# STM32G473xx register map
File version: 1.0
Registers are 32-bit, read-write, reset 0x0 unless marked. A register's access mark holds for its fields unless they carry their own. Offsets are from the block's base; [hi:lo] are bit positions; {n}, {i} and the like mark numbered series.

## TIM2 — TIM
Base 0x40000000
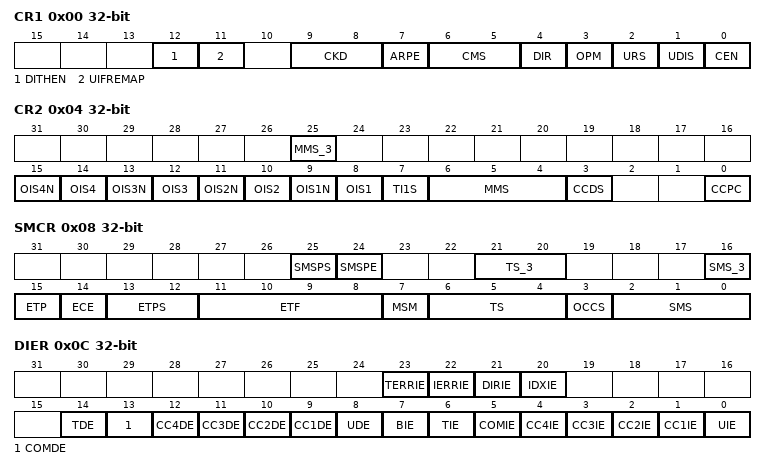
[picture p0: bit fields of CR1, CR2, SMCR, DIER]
0x00 CR1 — TIM control register 1
  [12] DITHEN — Dithering enable
  [11] UIFREMAP — Update interrupt flag remap
  [9:8] CKD — CKD[1:0] bits (clock division)
    0=DIV1 (tDTS=tCK_INT); 1=DIV2 (tDTS=2*tCK_INT); 2=DIV4 (tDTS=4*tCK_INT)
  [7] ARPE — Auto-reload preload enable
  [6:5] CMS — CMS[1:0] bits (Center-aligned mode selection)
  [4] DIR — Direction
    0=UP (Timer counter counts up); 1=DOWN (Timer counter counts down)
  [3] OPM — One pulse mode
    1=SINGLE (Counter stops counting at the next update event); 0=REPETITIVE (Counter is not stopped at update event)
  [2] URS — Update request source
    0=REGULAR (Counter overflow/underflow, Setting the UG bit or Update generation through the slave mode controller generates an update request); 1=COUNTER (Only counter overflow/underflow generates an update request)
  [1] UDIS — Update disable
  [0] CEN — Counter enable
0x04 CR2 — TIM control register 2
  [25] MMS_3 — MMS[3:0] bits (Master Mode Selection)
  [2n+7] OIS{n}N (n=1..4) — Output Idle state {n} (OC{n}N output)
  [2n+6] OIS{n} (n=1..4) — Output Idle state {n} (OC{n} output)
  [7] TI1S — TI1 Selection
  [6:4] MMS — MMS[3:0] bits (Master Mode Selection)
  [3] CCDS — Capture/Compare DMA Selection
    0=CC (CCx DMA request sent when CCx event occurs); 1=UPDATE (CCx DMA requests sent when update event occurs)
  [0] CCPC — Capture/Compare Preloaded Control
0x08 SMCR — TIM slave mode control register
  [25] SMSPS — SMS preload source
    0=TIMUPDATE (The SMS preload transfer is triggered by the Timer's Update event); 1=INDEX (The SMS preload transfer is triggered by the Index event)
  [24] SMSPE — SMS preload enable
  [21:20] TS_3 — TS[2:0] bits (Trigger selection)
  [16] SMS_3 — SMS[2:0] bits (Slave mode selection)
  [15] ETP — External trigger polarity
  [14] ECE — External clock enable
  [13:12] ETPS — ETPS[1:0] bits (External trigger prescaler)
  [11:8] ETF — ETF[3:0] bits (External trigger filter)
  [7] MSM — Master/slave mode
  [6:4] TS — TS[2:0] bits (Trigger selection)
  [3] OCCS — OCREF clear selection
  [2:0] SMS — SMS[2:0] bits (Slave mode selection)
0x0C DIER — TIM DMA/interrupt enable register
  [23] TERRIE — Encoder transition error enable
  [22] IERRIE — Encoder index error enable
  [21] DIRIE — Encoder direction change interrupt enable
  [20] IDXIE — Encoder index interrupt enable
  [14] TDE — Trigger DMA request enable
  [13] COMDE — COM DMA request enable
  [n+8] CC{n}DE (n=1..4) — Capture/Compare {n} DMA request enable
  [8] UDE — Update DMA request enable
  [7] BIE — Break interrupt enable
  [6] TIE — Trigger interrupt enable
  [5] COMIE — COM interrupt enable
  [n] CC{n}IE (n=1..4) — Capture/Compare {n} interrupt enable
  [0] UIE — Update interrupt enable
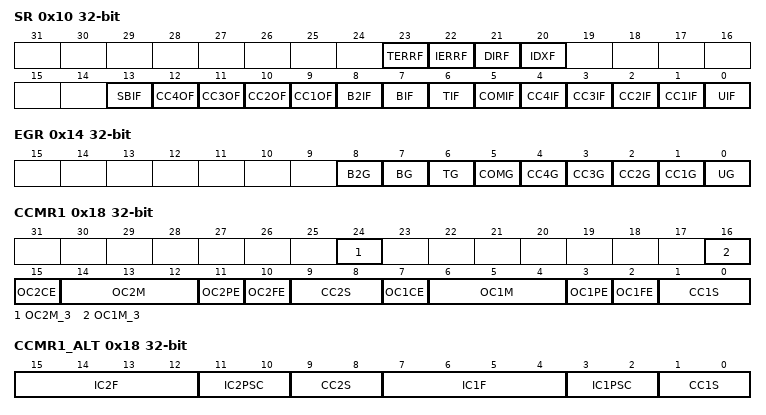
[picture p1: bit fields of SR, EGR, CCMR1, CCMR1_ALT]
0x10 SR — TIM status register
  [23] TERRF — Encoder transition error flag
  [22] IERRF — Encoder index error flag
  [21] DIRF — Encoder direction change interrupt flag
  [20] IDXF — Encoder index interrupt flag
  [13] SBIF — System Break interrupt Flag
  [n+8] CC{n}OF (n=1..4) — Capture/Compare {n} Overcapture Flag
  [8] B2IF — Break 2 interrupt Flag
  [7] BIF — Break interrupt Flag
  [6] TIF — Trigger interrupt Flag
  [5] COMIF — COM interrupt Flag
  [n] CC{n}IF (n=1..4) — Capture/Compare {n} interrupt Flag
  [0] UIF — Update interrupt Flag
0x14 EGR — TIM event generation register
  [8] B2G — Break 2 Generation
  [7] BG — Break Generation
  [6] TG — Trigger Generation
  [5] COMG — Capture/Compare Control Update Generation
  [n] CC{n}G (n=1..4) — Capture/Compare {n} Generation
  [0] UG — Update Generation
0x18 CCMR1 — TIM capture/compare mode register 1
  [24] OC2M_3 — OC2M[2:0] bits (Output Compare 2 Mode)
  [16] OC1M_3 — OC1M[2:0] bits (Output Compare 1 Mode)
  [15] OC2CE — Output Compare 2 Clear Enable
  [14:12] OC2M — OC2M[2:0] bits (Output Compare 2 Mode)
  [11] OC2PE — Output Compare 2 Preload enable
  [10] OC2FE — Output Compare 2 Fast enable
  [9:8] CC2S — CC2S[1:0] bits (Capture/Compare 2 Selection)
  [7] OC1CE — Output Compare 1 Clear Enable
  [6:4] OC1M — OC1M[2:0] bits (Output Compare 1 Mode)
  [3] OC1PE — Output Compare 1 Preload enable
  [2] OC1FE — Output Compare 1 Fast enable
  [1:0] CC1S — CC1S[1:0] bits (Capture/Compare 1 Selection)
0x18 CCMR1_ALT (alternate view of CCMR1) — TIM capture/compare mode register 1
  [15:12] IC2F — IC2F[3:0] bits (Input Capture 2 Filter)
  [11:10] IC2PSC — IC2PSC[1:0] bits (Input Capture 2 Prescaler)
  [9:8] CC2S — CC2S[1:0] bits (Capture/Compare 2 Selection)
  [7:4] IC1F — IC1F[3:0] bits (Input Capture 1 Filter)
  [3:2] IC1PSC — IC1PSC[1:0] bits (Input Capture 1 Prescaler)
  [1:0] CC1S — CC1S[1:0] bits (Capture/Compare 1 Selection)
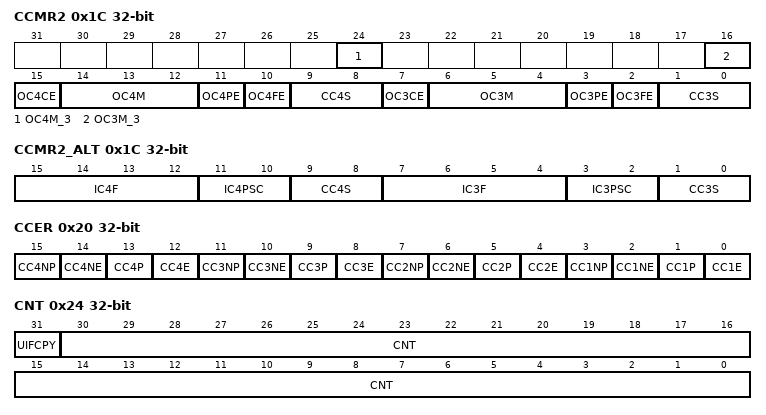
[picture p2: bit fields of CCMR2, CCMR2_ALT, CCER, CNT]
0x1C CCMR2 — TIM capture/compare mode register 2
  [24] OC4M_3 — OC4M[2:0] bits (Output Compare 4 Mode)
  [16] OC3M_3 — OC3M[2:0] bits (Output Compare 3 Mode)
  [15] OC4CE — Output Compare 4 Clear Enable
  [14:12] OC4M — OC4M[2:0] bits (Output Compare 4 Mode)
  [11] OC4PE — Output Compare 4 Preload enable
  [10] OC4FE — Output Compare 4 Fast enable
  [9:8] CC4S — CC4S[1:0] bits (Capture/Compare 4 Selection)
  [7] OC3CE — Output Compare 3 Clear Enable
  [6:4] OC3M — OC3M[2:0] bits (Output Compare 3 Mode)
  [3] OC3PE — Output Compare 3 Preload enable
  [2] OC3FE — Output Compare 3 Fast enable
  [1:0] CC3S — CC3S[1:0] bits (Capture/Compare 3 Selection)
0x1C CCMR2_ALT (alternate view of CCMR2) — TIM capture/compare mode register 2
  [15:12] IC4F — IC4F[3:0] bits (Input Capture 4 Filter)
  [11:10] IC4PSC — IC4PSC[1:0] bits (Input Capture 4 Prescaler)
  [9:8] CC4S — CC4S[1:0] bits (Capture/Compare 4 Selection)
  [7:4] IC3F — IC3F[3:0] bits (Input Capture 3 Filter)
  [3:2] IC3PSC — IC3PSC[1:0] bits (Input Capture 3 Prescaler)
  [1:0] CC3S — CC3S[1:0] bits (Capture/Compare 3 Selection)
0x20 CCER — TIM capture/compare enable register
  [4n-1] CC{n}NP (n=1..4) — Capture/Compare {n} Complementary output Polarity
  [4n-2] CC{n}NE (n=1..4) — Capture/Compare {n} Complementary output enable
  [4n-3] CC{n}P (n=1..4) — Capture/Compare {n} output Polarity
  [4n-4] CC{n}E (n=1..4) — Capture/Compare {n} output enable
0x24 CNT — TIM counter register
  [31] UIFCPY — Update interrupt flag copy (if UIFREMAP=1)
  [30:0] CNT — Counter Value
0x28 PSC — TIM prescaler
  [15:0] PSC — Prescaler Value
0x2C ARR — TIM auto-reload register
  [31:0] ARR — Actual auto-reload Value
{0x30+4i} CCR{i} (i=1..4) — TIM capture/compare register {i}
  [31:0] CCR{i} — Capture/Compare {i} Value
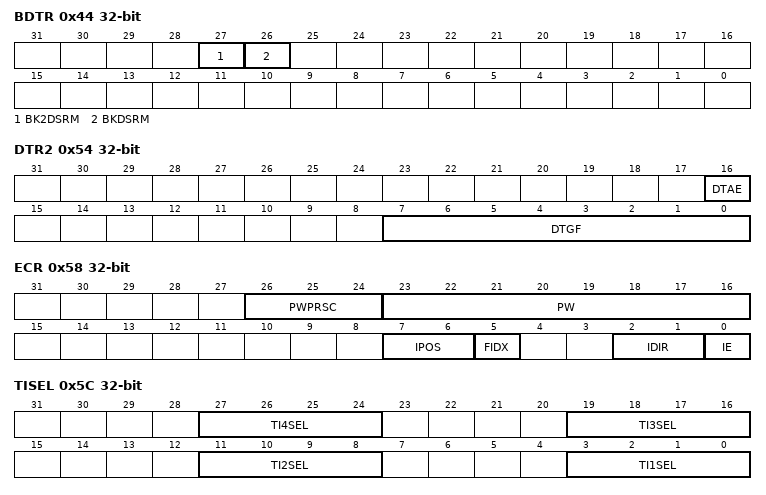
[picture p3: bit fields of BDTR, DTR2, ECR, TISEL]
0x44 BDTR — TIM break and dead-time register
  [27] BK2DSRM — Break2 disarming/re-arming
  [26] BKDSRM — Break disarming/re-arming
0x54 DTR2 — TIM deadtime register 2
  [16] DTAE — Deadtime asymmetric enable
  [7:0] DTGF — DTGF[7:0] bits (Deadtime falling edge generator setup)
0x58 ECR — TIM encoder control register
  [26:24] PWPRSC — PWPRSC[2:0] bits (Pulse width prescaler)
    0=Pulse on compare pulse width prescaler 1; 1=X2 (Pulse on compare pulse width prescaler 2); 2=X4 (Pulse on compare pulse width prescaler 4); 3=X8 (Pulse on compare pulse width prescaler 8); 4=X16 (Pulse on compare pulse width prescaler 16); 5=X32 (Pulse on compare pulse width prescaler 32); 6=X64 (Pulse on compare pulse width prescaler 64); 7=X128 (Pulse on compare pulse width prescaler 128)
  [23:16] PW — PW[7:0] bits (Pulse width)
  [7:6] IPOS — IPOS[1:0] bits (Index positioning)
    0=DOWN_DOWN (Index resets the counter when AB = 00); 1=DOWN_UP (Index resets the counter when AB = 01); 2=UP_DOWN (Index resets the counter when AB = 10); 3=UP_UP (Index resets the counter when AB = 11)
  [5] FIDX — First index enable
  [2:1] IDIR — IDIR[1:0] bits (Index direction)
    0=UP_DOWN (Index resets the counter whatever the direction); 1=UP (Index resets the counter when up-counting only); 2=DOWN (Index resets the counter when down-counting only)
  [0] IE — Index enable
0x5C TISEL — TIM Input Selection register
  [8n-5:8n-8] TI{n}SEL (n=1..4) — TI{n}SEL[3:0] bits (TIM1 TI{n} SEL)
0x60 AF1 — TIM alternate function option register 1
0x64 AF2 — TIM alternate function option register 2
0x68 OR — TIM option register
  [0] HSE32EN — HSE/32 clock enable
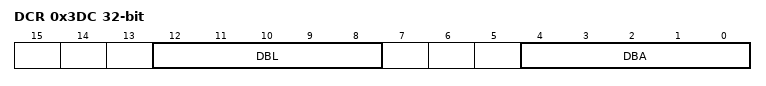
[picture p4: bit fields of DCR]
0x3DC DCR — TIM DMA control register
  [12:8] DBL — DBL[4:0] bits (DMA Burst Length)
  [4:0] DBA — DBA[4:0] bits (DMA Base Address)
0x3E0 DMAR — TIM DMA address for full transfer
  [31:0] DMAB — DMA register for burst accesses

## TIM3 — TIM
Base 0x40000400
Registers as TIM2; these are added or differ:
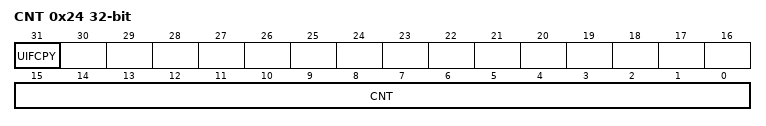
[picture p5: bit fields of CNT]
0x24 CNT — TIM counter register
  [31] UIFCPY — Update interrupt flag copy (if UIFREMAP=1)
  [15:0] CNT — Counter Value
0x2C ARR — TIM auto-reload register
  [15:0] ARR — Actual auto-reload Value
{0x30+4i} CCR{i} (i=1..4) — TIM capture/compare register {i}
  [15:0] CCR{i} — Capture/Compare {i} Value

## TIM4 — TIM
Base 0x40000800
Registers as TIM3; these are added or differ:
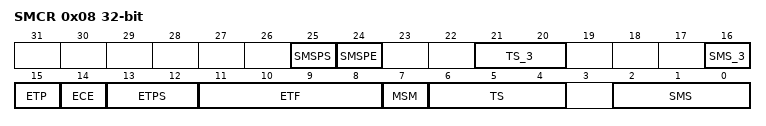
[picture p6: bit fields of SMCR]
0x08 SMCR — TIM slave mode control register
  [25] SMSPS — SMS preload source
    0=TIMUPDATE (The SMS preload transfer is triggered by the Timer's Update event); 1=INDEX (The SMS preload transfer is triggered by the Index event)
  [24] SMSPE — SMS preload enable
  [21:20] TS_3 — TS[2:0] bits (Trigger selection)
  [16] SMS_3 — SMS[2:0] bits (Slave mode selection)
  [15] ETP — External trigger polarity
  [14] ECE — External clock enable
  [13:12] ETPS — ETPS[1:0] bits (External trigger prescaler)
  [11:8] ETF — ETF[3:0] bits (External trigger filter)
  [7] MSM — Master/slave mode
  [6:4] TS — TS[2:0] bits (Trigger selection)
  [2:0] SMS — SMS[2:0] bits (Slave mode selection)

## TIM5 — TIM
Base 0x40000C00
Registers as TIM4; these are added or differ:
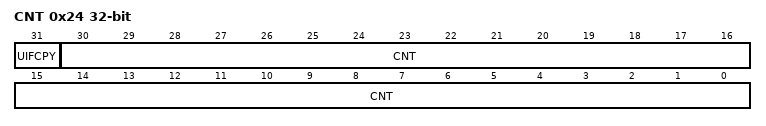
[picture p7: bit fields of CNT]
0x24 CNT — TIM counter register
  [31] UIFCPY — Update interrupt flag copy (if UIFREMAP=1)
  [30:0] CNT — Counter Value
0x2C ARR — TIM auto-reload register
  [31:0] ARR — Actual auto-reload Value
{0x30+4i} CCR{i} (i=1..4) — TIM capture/compare register {i}
  [31:0] CCR{i} — Capture/Compare {i} Value
